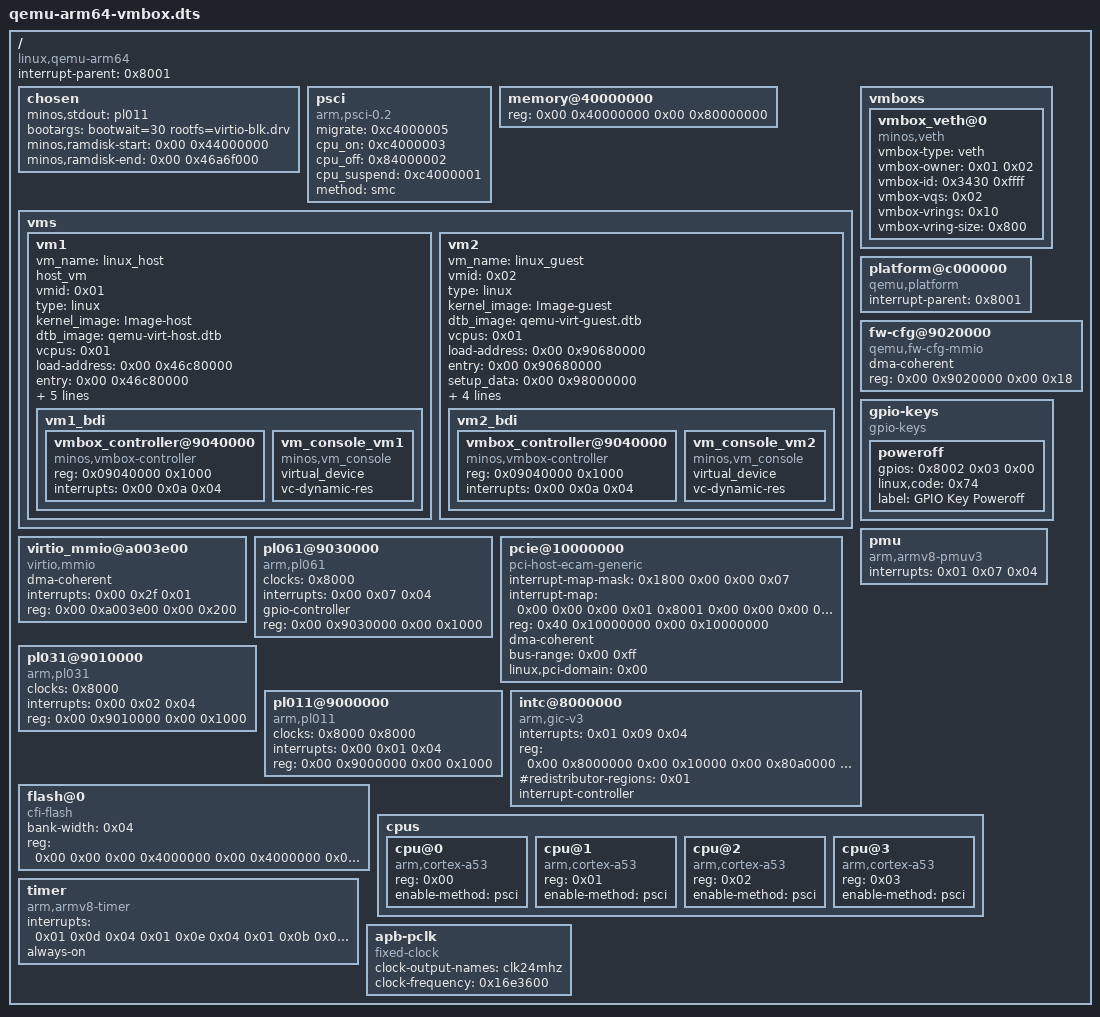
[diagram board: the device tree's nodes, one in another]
/dts-v1/;

/ {
	interrupt-parent = <0x8001>;
	#size-cells = <0x02>;
	#address-cells = <0x02>;
	compatible = "linux,qemu-arm64";

	chosen {
		minos,stdout = "pl011";
		bootargs = "bootwait=30 rootfs=virtio-blk.drv";
		minos,ramdisk-start = <0x00 0x44000000>;
		minos,ramdisk-end = <0x00 0x46a6f000>;
	};

	psci {
		migrate = <0xc4000005>;
		cpu_on = <0xc4000003>;
		cpu_off = <0x84000002>;
		cpu_suspend = <0xc4000001>;
		method = "smc";
		compatible = "arm,psci-0.2\0arm,psci";
	};

	memory@40000000 {
		device_type = "memory";
		reg = <0x00 0x40000000 0x00 0x80000000>;
	};

	vms {

		vm1 {
			device_type = "virtual_machine";
			vm_name = "linux_host";
			host_vm;
			vmid = <0x01>;
			type = "linux";
			kernel_image = "Image-host";
			dtb_image = "qemu-virt-host.dtb";
			vcpus = <0x01>;
			load-address = <0x00 0x46c80000>;
			entry = <0x00 0x46c80000>;
			setup_data = <0x00 0x50000000>;
			vcpu_affinity = <0x00>;
			cmdline = "console=hvc0 earlycon=dbcon,io,0x0 loglevel=8 consolelog=9 root=/dev/vda2 rw";
			memory = <0x00 0x46c00000 0x00 0x3fa00000>;

			vm1_bdi {
				#address-cells = <0x01>;
				#size-cells = <0x01>;

				vmbox_controller@9040000 {
					compatible = "minos,vmbox-controller";
					reg = <0x09040000 0x1000>;
					interrupts = <0x00 0x0a 0x04>;
				};

				vm_console_vm1 {
					virtual_device;
					vc-dynamic-res;
					compatible = "minos,vm_console";
					// reg = <0x20001000 0x2000>;
					// interrupts = <0x00 0x00 0x04>;
				};
			};
		};

		vm2 {
			device_type = "virtual_machine";
			vm_name = "linux_guest";
			vmid = <0x02>;
			type = "linux";
			kernel_image = "Image-guest";
			dtb_image = "qemu-virt-guest.dtb";
			// initrd_image = "guest1-repack.cpio.gz";
			vcpus = <0x01>;
			load-address = <0x00 0x90680000>;
			entry = <0x00 0x90680000>;
			setup_data = <0x00 0x98000000>;
			vcpu_affinity = <0x01 0x00 0x00 0x00>;
			
			// cmdline = "console=hvc0 earlycon=dbcon,io,0x0 loglevel=8 consolelog=9 root=/dev/vda2 ro rootwait init=/bin/sh";
			cmdline = "console=hvc0 earlycon=dbcon,io,0x0 loglevel=8 consolelog=9 root=/dev/vda rw rootwait init=/init";
			memory = <0x00 0x90000000 0x00 0x10000000>;

			vm2_bdi {
				#address-cells = <0x01>;
				#size-cells = <0x01>;

				vmbox_controller@9040000 {
					compatible = "minos,vmbox-controller";
					reg = <0x09040000 0x1000>;
					interrupts = <0x00 0x0a 0x04>;
				};

				vm_console_vm2 {
					virtual_device;
					vc-dynamic-res;
					compatible = "minos,vm_console";
					// reg = <0x20001000 0x2000>;
					// interrupts = <0x00 0x00 0x04>;
				};
			};
		};
	};

	vmboxs {
		vmbox_veth@0 {
			compatible = "minos,veth";
			vmbox-type = "veth";
	
			/*
			 * owner[0] = backend/server side
			 * owner[1] = frontend/client side
			 *
			 * 현재 구조에서는 VM1을 Guardian/receiver,
			 * VM2를 AI metadata sender로 볼 것이므로
			 * VM1=1, VM2=2 순서가 적절함.
			 */
			vmbox-owner = <0x01 0x02>;
	
			/*
			 * vmbox_veth Linux driver가 인식하는 device id.
			 */
			vmbox-id = <0x3430 0xffff>;
	
			/*
			 * veth는 TX/RX용 virtqueue 2개 필요.
			 */
			vmbox-vqs = <0x02>;
	
			/*
			 * vring 개수와 각 buffer 크기.
			 * 일단 기존 예시값 그대로 사용.
			 */
			vmbox-vrings = <0x10>;
			vmbox-vring-size = <0x800>;
		};
	};

	platform@c000000 {
		interrupt-parent = <0x8001>;
		ranges = <0x00 0x00 0xc000000 0x2000000>;
		#address-cells = <0x01>;
		#size-cells = <0x01>;
		compatible = "qemu,platform\0simple-bus";
	};

	fw-cfg@9020000 {
		dma-coherent;
		reg = <0x00 0x9020000 0x00 0x18>;
		compatible = "qemu,fw-cfg-mmio";
	};

	virtio_mmio@a003e00 {
		dma-coherent;
		interrupts = <0x00 0x2f 0x01>;
		reg = <0x00 0xa003e00 0x00 0x200>;
		compatible = "virtio,mmio";
	};

	gpio-keys {
		#address-cells = <0x01>;
		#size-cells = <0x00>;
		compatible = "gpio-keys";

		poweroff {
			gpios = <0x8002 0x03 0x00>;
			linux,code = <0x74>;
			label = "GPIO Key Poweroff";
		};
	};

	pl061@9030000 {
		phandle = <0x8002>;
		clock-names = "apb_pclk";
		clocks = <0x8000>;
		interrupts = <0x00 0x07 0x04>;
		gpio-controller;
		#gpio-cells = <0x02>;
		compatible = "arm,pl061\0arm,primecell";
		reg = <0x00 0x9030000 0x00 0x1000>;
	};

	pcie@10000000 {
		interrupt-map-mask = <0x1800 0x00 0x00 0x07>;
		interrupt-map = <0x00 0x00 0x00 0x01 0x8001 0x00 0x00 0x00 0x03 0x04 0x00 0x00 0x00 0x02 0x8001 0x00 0x00 0x00 0x04 0x04 0x00 0x00 0x00 0x03 0x8001 0x00 0x00 0x00 0x05 0x04 0x00 0x00 0x00 0x04 0x8001 0x00 0x00 0x00 0x06 0x04 0x800 0x00 0x00 0x01 0x8001 0x00 0x00 0x00 0x04 0x04 0x800 0x00 0x00 0x02 0x8001 0x00 0x00 0x00 0x05 0x04 0x800 0x00 0x00 0x03 0x8001 0x00 0x00 0x00 0x06 0x04 0x800 0x00 0x00 0x04 0x8001 0x00 0x00 0x00 0x03 0x04 0x1000 0x00 0x00 0x01 0x8001 0x00 0x00 0x00 0x05 0x04 0x1000 0x00 0x00 0x02 0x8001 0x00 0x00 0x00 0x06 0x04 0x1000 0x00 0x00 0x03 0x8001 0x00 0x00 0x00 0x03 0x04 0x1000 0x00 0x00 0x04 0x8001 0x00 0x00 0x00 0x04 0x04 0x1800 0x00 0x00 0x01 0x8001 0x00 0x00 0x00 0x06 0x04 0x1800 0x00 0x00 0x02 0x8001 0x00 0x00 0x00 0x03 0x04 0x1800 0x00 0x00 0x03 0x8001 0x00 0x00 0x00 0x04 0x04 0x1800 0x00 0x00 0x04 0x8001 0x00 0x00 0x00 0x05 0x04>;
		#interrupt-cells = <0x01>;
		ranges = <0x1000000 0x00 0x00 0x00 0x3eff0000 0x00 0x10000 0x2000000 0x00 0x10000000 0x00 0x10000000 0x00 0x2eff0000 0x3000000 0x80 0x00 0x80 0x00 0x80 0x00>;
		reg = <0x40 0x10000000 0x00 0x10000000>;
		dma-coherent;
		bus-range = <0x00 0xff>;
		linux,pci-domain = <0x00>;
		#size-cells = <0x02>;
		#address-cells = <0x03>;
		device_type = "pci";
		compatible = "pci-host-ecam-generic";
	};

	pl031@9010000 {
		clock-names = "apb_pclk";
		clocks = <0x8000>;
		interrupts = <0x00 0x02 0x04>;
		reg = <0x00 0x9010000 0x00 0x1000>;
		compatible = "arm,pl031\0arm,primecell";
	};

	pl011@9000000 {
		clock-names = "uartclk\0apb_pclk";
		clocks = <0x8000 0x8000>;
		interrupts = <0x00 0x01 0x04>;
		reg = <0x00 0x9000000 0x00 0x1000>;
		compatible = "arm,pl011\0arm,primecell";
	};

	pmu {
		interrupts = <0x01 0x07 0x04>;
		compatible = "arm,armv8-pmuv3";
	};

	intc@8000000 {
		phandle = <0x8001>;
		interrupts = <0x01 0x09 0x04>;
		reg = <0x00 0x8000000 0x00 0x10000 0x00 0x80a0000 0x00 0x200000 0x00 0x8010000 0x00 0x2000 0x00 0x8030000 0x00 0x2000 0x00 0x8040000 0x00 0x2000>;
		#redistributor-regions = <0x01>;
		compatible = "arm,gic-v3";
		ranges;
		#size-cells = <0x02>;
		#address-cells = <0x02>;
		interrupt-controller;
		#interrupt-cells = <0x03>;
	};

	flash@0 {
		bank-width = <0x04>;
		reg = <0x00 0x00 0x00 0x4000000 0x00 0x4000000 0x00 0x4000000>;
		compatible = "cfi-flash";
	};

	cpus {
		#size-cells = <0x00>;
		#address-cells = <0x01>;

		cpu@0 {
			reg = <0x00>;
			enable-method = "psci";
			compatible = "arm,cortex-a53";
			device_type = "cpu";
		};

		cpu@1 {
			reg = <0x01>;
			enable-method = "psci";
			compatible = "arm,cortex-a53";
			device_type = "cpu";
		};

		cpu@2 {
			reg = <0x02>;
			enable-method = "psci";
			compatible = "arm,cortex-a53";
			device_type = "cpu";
		};

		cpu@3 {
			reg = <0x03>;
			enable-method = "psci";
			compatible = "arm,cortex-a53";
			device_type = "cpu";
		};
	};

	timer {
		interrupts = <0x01 0x0d 0x04 0x01 0x0e 0x04 0x01 0x0b 0x04 0x01 0x0a 0x04>;
		always-on;
		compatible = "arm,armv8-timer\0arm,armv7-timer";
	};

	apb-pclk {
		phandle = <0x8000>;
		clock-output-names = "clk24mhz";
		clock-frequency = <0x16e3600>;
		#clock-cells = <0x00>;
		compatible = "fixed-clock";
	};
};
